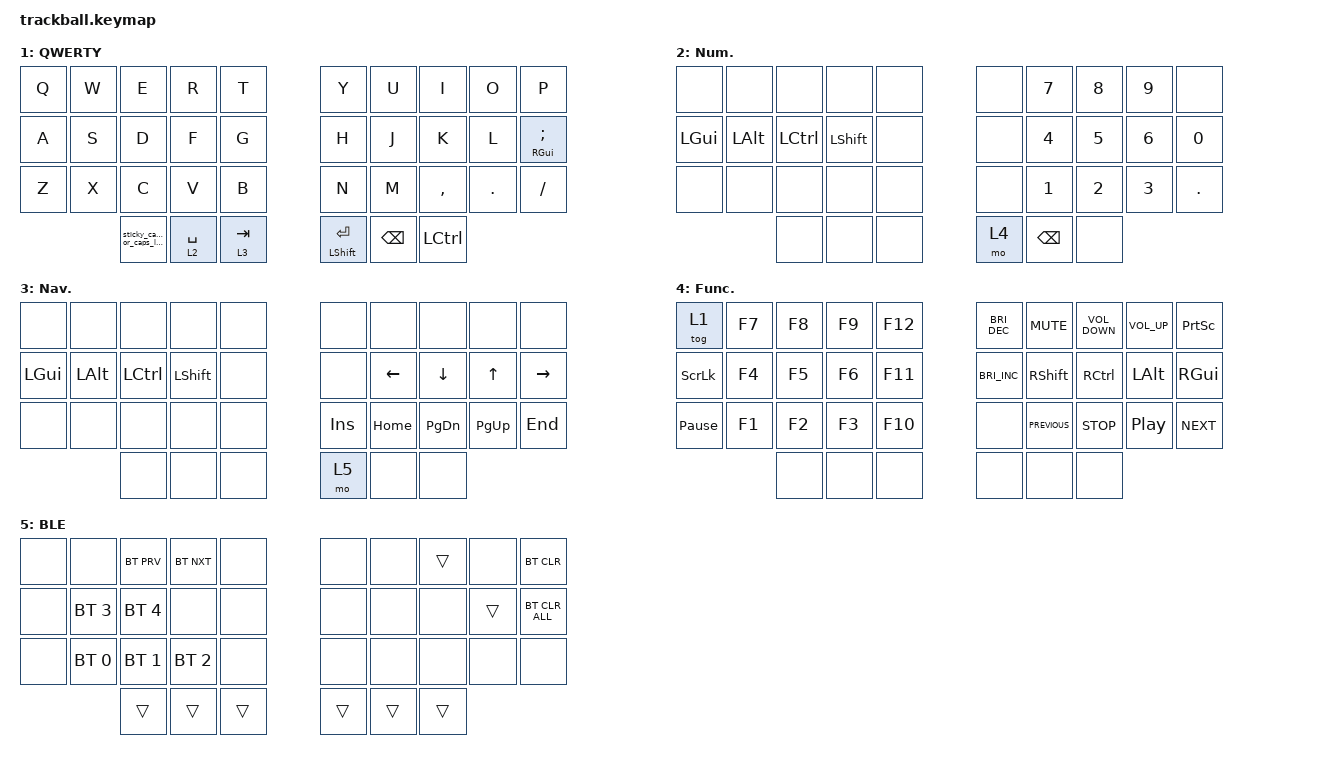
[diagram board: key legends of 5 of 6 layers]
/*
 * Copyright (c) 2020 The ZMK Contributors
 *
 * SPDX-License-Identifier: MIT
 */

#include <behaviors.dtsi>
#include <dt-bindings/zmk/keys.h>
#include <dt-bindings/zmk/bt.h>
#include <dt-bindings/zmk/outputs.h>

/ {
    combos {
        compatible = "zmk,combos";

        arobase {
            bindings = <&kp AT>;
            key-positions = <1 11>;
        };

        grave {
            bindings = <&kp GRAVE>;
            key-positions = <11 21>;
        };

        escape {
            bindings = <&kp ESCAPE>;
            key-positions = <1 2>;
        };

        cut {
            bindings = <&kp LC(X)>;
            key-positions = <11 12>;
        };

        copy {
            bindings = <&kp LC(C)>;
            key-positions = <21 22>;
        };

        hashtag {
            bindings = <&kp HASH>;
            key-positions = <2 12>;
        };

        backslash {
            bindings = <&kp BACKSLASH>;
            key-positions = <12 22>;
        };

        enter {
            bindings = <&kp ENTER>;
            key-positions = <2 3>;
        };

        tab {
            bindings = <&kp TAB>;
            key-positions = <12 13>;
        };

        paste {
            bindings = <&kp LC(V)>;
            key-positions = <22 23>;
        };

        dollar {
            bindings = <&kp DOLLAR>;
            key-positions = <3 13>;
        };

        equal {
            bindings = <&kp EQUAL>;
            key-positions = <13 23>;
        };

        percent {
            bindings = <&kp PERCENT>;
            key-positions = <4 14>;
        };

        tilde {
            bindings = <&kp TILDE>;
            key-positions = <14 24>;
        };

        caret {
            bindings = <&kp CARET>;
            key-positions = <5 15>;
        };

        underscore {
            bindings = <&kp UNDERSCORE>;
            key-positions = <15 25>;
        };

        plus {
            bindings = <&kp KP_PLUS>;
            key-positions = <6 16>;
        };

        minus {
            bindings = <&mt UNDERSCORE MINUS>;
            key-positions = <16 26>;
        };

        backspace {
            bindings = <&kp BACKSPACE>;
            key-positions = <6 7>;
        };

        left_paren {
            bindings = <&mt LESS_THAN LEFT_PARENTHESIS>;
            key-positions = <16 17>;
        };

        left_bracket {
            bindings = <&mt LEFT_BRACE LEFT_BRACKET>;
            key-positions = <26 27>;
        };

        asterisk {
            bindings = <&kp ASTERISK>;
            key-positions = <7 17>;
        };

        slash {
            bindings = <&mt BACKSLASH SLASH>;
            key-positions = <17 27>;
        };

        delete {
            bindings = <&kp DEL>;
            key-positions = <7 8>;
        };

        right_paren {
            bindings = <&mt GREATER_THAN RIGHT_PARENTHESIS>;
            key-positions = <17 18>;
        };

        right_bracket {
            bindings = <&mt RIGHT_BRACE RIGHT_BRACKET>;
            key-positions = <27 28>;
        };

        ampersand {
            bindings = <&kp AMPERSAND>;
            key-positions = <8 18>;
        };

        pipe {
            bindings = <&kp PIPE>;
            key-positions = <18 28>;
        };
    };

    behaviors {
        left_hand: left_hand {
            compatible = "zmk,behavior-hold-tap";
            label = "LEFT_HAND";
            bindings = <&kp>, <&kp>;

            #binding-cells = <2>;
            flavor = "balanced";
            tapping-term-ms = <280>;
            hold-trigger-key-positions = <5 6 7 8 9 15 16 17 18 19 25 26 27 28 29 30 31 32 33 34 35>;
            hold-trigger-on-release;
            require-prior-idle-ms = <150>;
            quick-tap-ms = <175>;
        };

        right_hand: right_hand {
            compatible = "zmk,behavior-hold-tap";
            label = "RIGHT_HAND";
            bindings = <&kp>, <&kp>;

            #binding-cells = <2>;
            flavor = "balanced";
            tapping-term-ms = <280>;
            hold-trigger-on-release;
            hold-trigger-key-positions = <0 1 2 3 4 10 11 12 13 14 20 21 25 23 24 30 31 32 33 34 35>;
            require-prior-idle-ms = <150>;
            quick-tap-ms = <175>;
        };

        sticky_capital_or_caps_lock: sticky_capital_or_caps_lock {
            compatible = "zmk,behavior-tap-dance";
            label = "STICKY_CAPITAL_OR_CAPS_LOCK";
            #binding-cells = <0>;
            bindings = <&sk LEFT_SHIFT>, <&custom_caps_behavior>;
        };

        custom_caps_behavior: custom_caps_behavior {
            compatible = "zmk,behavior-caps-word";
            label = "CUSTOM_CAPS_BEHAVIOR";
            #binding-cells = <0>;
            continue-list = <A B C D E F G H I J K L M N O P Q R S T U V W X Y Z NUMBER_1 NUMBER_2 NUMBER_3 NUMBER_4 NUMBER_5 NUMBER_6 NUMBER_7 NUMBER_8 NUMBER_9 UNDERSCORE DELETE BACKSPACE>;
        };
    };

    keymap {
        compatible = "zmk,keymap";

        Colemak {
            // -----------------------------------------------------------------------------------------
            // |  TAB |  Q  |  W  |  E  |  R  |  T  |   |  Y  |  U   |  I  |  O  |  P  | BKSP |
            // | CTRL |  A  |  S  |  D  |  F  |  G  |   |  H  |  J   |  K  |  L  |  ;  |  '   |
            // | SHFT |  Z  |  X  |  C  |  V  |  B  |   |  N  |  M   |  ,  |  .  |  /  | ESC  |
            //                    | GUI | LWR | SPC |   | ENT | RSE  | ALT |

            bindings = <
&kp Q              &kp W                  &kp F                         &kp P                    &kp B        &kp J                 &kp L                      &kp U                        &kp Y                   &mt DOUBLE_QUOTES SINGLE_QUOTE
&left_hand LGUI A  &left_hand LEFT_ALT R  &left_hand LEFT_CONTROL S     &left_hand LEFT_SHIFT T  &kp G        &kp M                 &right_hand RIGHT_SHIFT N  &right_hand RIGHT_CONTROL E  &right_hand LEFT_ALT I  &right_hand RIGHT_GUI O
&kp Z              &kp X                  &kp C                         &kp D                    &kp V        &kp K                 &kp H                      &mt SEMI COMMA               &mt COLON PERIOD        &mt QUESTION EXCLAMATION
                                                 &sticky_capital_or_caps_lock  &lt 2 SPACE              &lt 3 TAB    &mt LEFT_SHIFT ENTER  &kp BACKSPACE &kp RIGHT_ALT
&kp NUMBER_0    &kp NUMBER_1    &kp NUMBER_2
            >;

            label = "Colemak";
        };

        Qwerty {
            bindings = <
&kp Q  &kp W  &kp E                         &kp R        &kp T        &kp Y                 &kp U          &kp I      &kp O    &kp P
&kp A  &kp S  &kp D                         &kp F        &kp G        &kp H                 &kp J          &kp K      &kp L    &right_hand RIGHT_GUI SEMICOLON
&kp Z  &kp X  &kp C                         &kp V        &kp B        &kp N                 &kp M          &kp COMMA  &kp DOT  &kp FSLH
                      &sticky_capital_or_caps_lock  &lt 2 SPACE  &lt 3 TAB    &mt LEFT_SHIFT ENTER  &kp BACKSPACE  &kp LCTRL
            >;

            label = "QWERTY";
        };

        Numpad {
            // -----------------------------------------------------------------------------------------
            // |  TAB |  1  |  2  |  3  |  4  |  5  |   |  6  |  7  |  8  |  9  |  0  | BKSP |
            // | BTCLR| BT1 | BT2 | BT3 | BT4 | BT5 |   | LFT | DWN |  UP | RGT |     |      |
            // | SHFT |     |     |     |     |     |   |     |     |     |     |     |      |
            //                    | GUI |     | SPC |   | ENT |     | ALT |

            bindings = <
&none     &none         &none             &none           &none    &none  &kp NUMBER_7   &kp NUMBER_8  &kp NUMBER_9  &none
&kp LGUI  &kp LEFT_ALT  &kp LEFT_CONTROL  &kp LEFT_SHIFT  &none    &none  &kp NUMBER_4   &kp NUMBER_5  &kp NUMBER_6  &kp NUMBER_0
&none     &none         &none             &none           &none    &none  &kp NUMBER_1   &kp NUMBER_2  &kp NUMBER_3  &kp DOT
                               &none             &none           &none    &mo 4  &kp BACKSPACE  &none
            >;

            label = "Num.";
        };

        Navigation {
            // -----------------------------------------------------------------------------------------
            // |  TAB |  !  |  @  |  #  |  $  |  %  |   |  ^  |  &  |  *  |  (  |  )  | BKSP |
            // | CTRL |     |     |     |     |     |   |  -  |  =  |  [  |  ]  |  \  |  `   |
            // | SHFT |     |     |     |     |     |   |  _  |  +  |  {  |  }  | "|" |  ~   |
            //                    | GUI |     | SPC |   | ENT |     | ALT |

            bindings = <
&none     &none         &none             &none       &none    &none       &none     &none           &none         &none
&kp LGUI  &kp LEFT_ALT  &kp LEFT_CONTROL  &kp LSHIFT  &none    &none       &kp LEFT  &kp DOWN_ARROW  &kp UP_ARROW  &kp RIGHT_ARROW
&none     &none         &none             &none       &none    &kp INSERT  &kp HOME  &kp PAGE_DOWN   &kp PAGE_UP   &kp END
                               &none             &none       &none    &mo 5       &none     &none
            >;

            label = "Nav.";
        };

        Function {
            bindings = <
&tog 1           &kp F7  &kp F8  &kp F9  &kp F12    &kp C_BRI_DEC         &kp K_MUTE       &kp C_VOLUME_DOWN  &kp C_VOLUME_UP   &kp PRINTSCREEN
&kp SCROLLLOCK   &kp F4  &kp F5  &kp F6  &kp F11    &kp C_BRIGHTNESS_INC  &kp RIGHT_SHIFT  &kp RIGHT_CONTROL  &kp LEFT_ALT      &kp RIGHT_GUI
&kp PAUSE_BREAK  &kp F1  &kp F2  &kp F3  &kp F10    &none                 &kp C_PREVIOUS   &kp C_STOP         &kp C_PLAY_PAUSE  &kp C_NEXT
                                &none   &none   &none      &none                 &none            &none
            >;

            label = "Func.";
        };

        Bluetooth {
            bindings = <
&none  &none         &bt BT_PRV    &bt BT_NXT    &none     &none   &none   &trans  &none   &bt BT_CLR
&none  &bt BT_SEL 3  &bt BT_SEL 4  &none         &none     &none   &none   &none   &trans  &bt BT_CLR_ALL
&none  &bt BT_SEL 0  &bt BT_SEL 1  &bt BT_SEL 2  &none     &none   &none   &none   &none   &none
                             &trans        &trans        &trans    &trans  &trans  &trans
            >;

            label = "BLE";
        };
    };

    conditional_layers { compatible = "zmk,conditional-layers"; };
};
